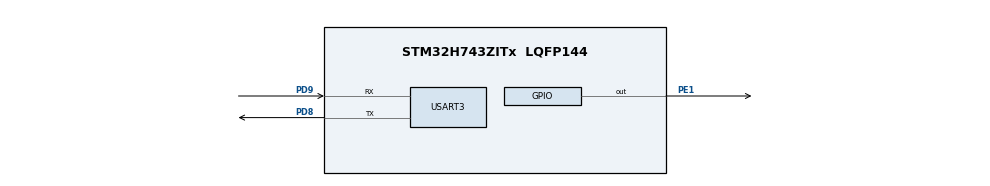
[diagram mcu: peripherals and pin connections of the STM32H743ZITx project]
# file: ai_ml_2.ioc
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CORTEX_M7.CPU_DCache=Enabled
CORTEX_M7.CPU_ICache=Enabled
CORTEX_M7.default_mode_Activation=1
Mcu.Family=STM32H7
Mcu.Name=STM32H743ZITx
Mcu.Package=LQFP144
NVIC.PriorityGroup=NVIC_PRIORITYGROUP_4
PC14-OSC32_IN\ (OSC32_IN).Mode=LSE-External-Oscillator
PC14-OSC32_IN\ (OSC32_IN).Signal=RCC_OSC32_IN
PC15-OSC32_OUT\ (OSC32_OUT).Mode=LSE-External-Oscillator
PC15-OSC32_OUT\ (OSC32_OUT).Signal=RCC_OSC32_OUT
PD8.Mode=Asynchronous
PD8.Signal=USART3_TX
PD9.Mode=Asynchronous
PD9.Signal=USART3_RX
PE1.Signal=GPIO_Output
PH0-OSC_IN\ (PH0).Mode=HSE-External-Oscillator
PH0-OSC_IN\ (PH0).Signal=RCC_OSC_IN
PH1-OSC_OUT\ (PH1).Mode=HSE-External-Oscillator
PH1-OSC_OUT\ (PH1).Signal=RCC_OSC_OUT
ProjectManager.HeapSize=0x800
ProjectManager.StackSize=0x800
ProjectManager.TargetToolchain=STM32CubeIDE
RCC.ADCFreq_Value=129000000
RCC.APB1Freq_Value=120000000
RCC.APB2Freq_Value=120000000
RCC.APB3Freq_Value=120000000
RCC.APB4Freq_Value=120000000
RCC.CortexFreq_Value=480000000
RCC.D1PPRE=RCC_APB3_DIV2
RCC.D2PPRE1=RCC_APB1_DIV2
RCC.D2PPRE2=RCC_APB2_DIV2
RCC.D3PPRE=RCC_APB4_DIV2
RCC.DIVM1=4
RCC.DIVN1=60
RCC.HCLKFreq_Value=240000000
RCC.HPRE=RCC_HCLK_DIV2
RCC.HSE_VALUE=8000000
RCC.PLL2FRACN=0
RCC.PLL3FRACN=0
RCC.PLLFRACN=0
RCC.SYSCLKFreq_VALUE=480000000
RCC.SYSCLKSource=RCC_SYSCLKSOURCE_PLLCLK
RCC.USBFreq_Value=480000000
STMicroelectronics.X-CUBE-AI.9.0.0.ActivationBufferSizeList=128
STMicroelectronics.X-CUBE-AI.9.0.0.ActivationBuffers=pool0
STMicroelectronics.X-CUBE-AI.9.0.0.ActivationNames=pool0
STMicroelectronics.X-CUBE-AI.9.0.0.ActivationSizes=AI_NETWORK_DATA_ACTIVATION_1_SIZE
STMicroelectronics.X-CUBE-AI.9.0.0.ApplicationCcDeviceJjApplication=ApplicationTemplate
STMicroelectronics.X-CUBE-AI.9.0.0.HeapSize=0x800
STMicroelectronics.X-CUBE-AI.9.0.0.InternalRamActivationBufferMaxSize=AI_NETWORK_DATA_ACTIVATIONS_SIZE
STMicroelectronics.X-CUBE-AI.9.0.0.LatestDirectoryUsed-3daab31856350568c4daed4f92a2e885c80895c0f46f9eb44de7cb06f3eb3ba4=C\:\\Users\\denni\\Downloads
STMicroelectronics.X-CUBE-AI.9.0.0.MaximumNumberOfInputLayer=1
STMicroelectronics.X-CUBE-AI.9.0.0.MaximumNumberOfOutputLayer=1
STMicroelectronics.X-CUBE-AI.9.0.0.MaximumSizeOfInputLayer=1
STMicroelectronics.X-CUBE-AI.9.0.0.MaximumSizeOfOutputLayer=1
STMicroelectronics.X-CUBE-AI.9.0.0.ModelActualCompression-3daab31856350568c4daed4f92a2e885c80895c0f46f9eb44de7cb06f3eb3ba4=0.0
STMicroelectronics.X-CUBE-AI.9.0.0.ModelCompression-3daab31856350568c4daed4f92a2e885c80895c0f46f9eb44de7cb06f3eb3ba4=None
STMicroelectronics.X-CUBE-AI.9.0.0.ModelFlashOccupation-3daab31856350568c4daed4f92a2e885c80895c0f46f9eb44de7cb06f3eb3ba4=1284
STMicroelectronics.X-CUBE-AI.9.0.0.ModelHashList=3daab31856350568c4daed4f92a2e885c80895c0f46f9eb44de7cb06f3eb3ba4
STMicroelectronics.X-CUBE-AI.9.0.0.ModelKind-3daab31856350568c4daed4f92a2e885c80895c0f46f9eb44de7cb06f3eb3ba4=TFLITE
STMicroelectronics.X-CUBE-AI.9.0.0.ModelMacc-3daab31856350568c4daed4f92a2e885c80895c0f46f9eb44de7cb06f3eb3ba4=353
STMicroelectronics.X-CUBE-AI.9.0.0.ModelName-3daab31856350568c4daed4f92a2e885c80895c0f46f9eb44de7cb06f3eb3ba4=network
STMicroelectronics.X-CUBE-AI.9.0.0.ModelNameList=network
STMicroelectronics.X-CUBE-AI.9.0.0.ModelRamOccupation-3daab31856350568c4daed4f92a2e885c80895c0f46f9eb44de7cb06f3eb3ba4=128
STMicroelectronics.X-CUBE-AI.9.0.0.ModelStructureFile-3daab31856350568c4daed4f92a2e885c80895c0f46f9eb44de7cb06f3eb3ba4=C\:\\Users\\denni\\Downloads\\sine_model.tflite
STMicroelectronics.X-CUBE-AI.9.0.0.ModelType-3daab31856350568c4daed4f92a2e885c80895c0f46f9eb44de7cb06f3eb3ba4=STM32Cube.AI MCU runtime
STMicroelectronics.X-CUBE-AI.9.0.0.ReadyForCodeGeneration=true
STMicroelectronics.X-CUBE-AI.9.0.0.StackSize=0x800
STMicroelectronics.X-CUBE-AI.9.0.0.WorkingBufferStartAddrList=0xFFFFFFFF
STMicroelectronics.X-CUBE-AI.9.0.0.XAaCUBEAaAICcArtificialOoIntelligenceJjCore=true
STMicroelectronics.X-CUBE-AI.9.0.0.copyWeightToRam=false
STMicroelectronics.X-CUBE-AI.9.0.0.copyWeightToRam-3daab31856350568c4daed4f92a2e885c80895c0f46f9eb44de7cb06f3eb3ba4=false
STMicroelectronics.X-CUBE-AI.9.0.0.customLayerConfigEnabled=false
STMicroelectronics.X-CUBE-AI.9.0.0.customLayerConfigEnabled-3daab31856350568c4daed4f92a2e885c80895c0f46f9eb44de7cb06f3eb3ba4=false
STMicroelectronics.X-CUBE-AI.9.0.0.noOnnxIoTranspose=false
STMicroelectronics.X-CUBE-AI.9.0.0.noOnnxIoTranspose-3daab31856350568c4daed4f92a2e885c80895c0f46f9eb44de7cb06f3eb3ba4=false
STMicroelectronics.X-CUBE-AI.9.0.0.useInputAllocation=true
STMicroelectronics.X-CUBE-AI.9.0.0.useInputAllocation-3daab31856350568c4daed4f92a2e885c80895c0f46f9eb44de7cb06f3eb3ba4=true
STMicroelectronics.X-CUBE-AI.9.0.0.useOutputAllocation=true
STMicroelectronics.X-CUBE-AI.9.0.0.useOutputAllocation-3daab31856350568c4daed4f92a2e885c80895c0f46f9eb44de7cb06f3eb3ba4=true
USART3.VirtualMode-Asynchronous=VM_ASYNC
VP_STMicroelectronics.X-CUBE-AI_VS_ArtificialOoIntelligenceJjXAaCUBEAaAI_9.0.0.Mode=ArtificialOoIntelligenceJjXAaCUBEAaAI
VP_STMicroelectronics.X-CUBE-AI_VS_DeviceJjApplication_9.0.0.Mode=DeviceJjApplication
board=custom

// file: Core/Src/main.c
/* USER CODE BEGIN Header */
/**
  ******************************************************************************
  * @file           : main.c
  * @brief          : Main program body
  ******************************************************************************
  * @attention
  *
  * Copyright (c) 2024 STMicroelectronics.
  * All rights reserved.
  *
  * This software is licensed under terms that can be found in the LICENSE file
  * in the root directory of this software component.
  * If no LICENSE file comes with this software, it is provided AS-IS.
  *
  ******************************************************************************
  */
/* USER CODE END Header */
#include "main.h"
#include "usart.h"
#include "gpio.h"
#include "app_x-cube-ai.h"

void SystemClock_Config(void);
static void MPU_Config(void);

int main(void)
{

  /* USER CODE BEGIN 1 */
	//uint32_t in_number = 0;
	//uint32_t out_number = 0;
  /* USER CODE END 1 */

  /* MPU Configuration--------------------------------------------------------*/
  MPU_Config();

  /* Enable the CPU Cache */

  /* Enable I-Cache---------------------------------------------------------*/
  SCB_EnableICache();

  /* Enable D-Cache---------------------------------------------------------*/
  SCB_EnableDCache();

  /* MCU Configuration--------------------------------------------------------*/

  /* Reset of all peripherals, Initializes the Flash interface and the Systick. */
  HAL_Init();

  /* Configure the system clock */
  SystemClock_Config();

  /* Initialize all configured peripherals */
  MX_GPIO_Init();
  MX_USART3_UART_Init();
  MX_X_CUBE_AI_Init();

  /* Infinite loop */
  while (1)
  {
	  HAL_GPIO_WritePin(GPIOE,GPIO_PIN_1,GPIO_PIN_SET);
  MX_X_CUBE_AI_Process();
  }
}

void SystemClock_Config(void)
{
  RCC_OscInitTypeDef RCC_OscInitStruct = {0};
  RCC_ClkInitTypeDef RCC_ClkInitStruct = {0};

  /** Supply configuration update enable
  */
  HAL_PWREx_ConfigSupply(PWR_LDO_SUPPLY);

  /** Configure the main internal regulator output voltage
  */
  __HAL_PWR_VOLTAGESCALING_CONFIG(PWR_REGULATOR_VOLTAGE_SCALE1);

  while(!__HAL_PWR_GET_FLAG(PWR_FLAG_VOSRDY)) {}

  __HAL_RCC_SYSCFG_CLK_ENABLE();
  __HAL_PWR_VOLTAGESCALING_CONFIG(PWR_REGULATOR_VOLTAGE_SCALE0);

  while(!__HAL_PWR_GET_FLAG(PWR_FLAG_VOSRDY)) {}

  /** Initializes the RCC Oscillators according to the specified parameters
  * in the RCC_OscInitTypeDef structure.
  */
  RCC_OscInitStruct.OscillatorType = RCC_OSCILLATORTYPE_HSI;
  RCC_OscInitStruct.HSIState = RCC_HSI_DIV1;
  RCC_OscInitStruct.HSICalibrationValue = RCC_HSICALIBRATION_DEFAULT;
  RCC_OscInitStruct.PLL.PLLState = RCC_PLL_ON;
  RCC_OscInitStruct.PLL.PLLSource = RCC_PLLSOURCE_HSI;
  RCC_OscInitStruct.PLL.PLLM = 4;
  RCC_OscInitStruct.PLL.PLLN = 60;
  RCC_OscInitStruct.PLL.PLLP = 2;
  RCC_OscInitStruct.PLL.PLLQ = 2;
  RCC_OscInitStruct.PLL.PLLR = 2;
  RCC_OscInitStruct.PLL.PLLRGE = RCC_PLL1VCIRANGE_3;
  RCC_OscInitStruct.PLL.PLLVCOSEL = RCC_PLL1VCOWIDE;
  RCC_OscInitStruct.PLL.PLLFRACN = 0;
  if (HAL_RCC_OscConfig(&RCC_OscInitStruct) != HAL_OK)
  {
    Error_Handler();
  }

  /** Initializes the CPU, AHB and APB buses clocks
  */
  RCC_ClkInitStruct.ClockType = RCC_CLOCKTYPE_HCLK|RCC_CLOCKTYPE_SYSCLK
                              |RCC_CLOCKTYPE_PCLK1|RCC_CLOCKTYPE_PCLK2
                              |RCC_CLOCKTYPE_D3PCLK1|RCC_CLOCKTYPE_D1PCLK1;
  RCC_ClkInitStruct.SYSCLKSource = RCC_SYSCLKSOURCE_PLLCLK;
  RCC_ClkInitStruct.SYSCLKDivider = RCC_SYSCLK_DIV1;
  RCC_ClkInitStruct.AHBCLKDivider = RCC_HCLK_DIV2;
  RCC_ClkInitStruct.APB3CLKDivider = RCC_APB3_DIV2;
  RCC_ClkInitStruct.APB1CLKDivider = RCC_APB1_DIV2;
  RCC_ClkInitStruct.APB2CLKDivider = RCC_APB2_DIV2;
  RCC_ClkInitStruct.APB4CLKDivider = RCC_APB4_DIV2;

  if (HAL_RCC_ClockConfig(&RCC_ClkInitStruct, FLASH_LATENCY_4) != HAL_OK)
  {
    Error_Handler();
  }
}

 /* MPU Configuration */

void MPU_Config(void)
{
  MPU_Region_InitTypeDef MPU_InitStruct = {0};

  /* Disables the MPU */
  HAL_MPU_Disable();

  /** Initializes and configures the Region and the memory to be protected
  */
  MPU_InitStruct.Enable = MPU_REGION_ENABLE;
  MPU_InitStruct.Number = MPU_REGION_NUMBER0;
  MPU_InitStruct.BaseAddress = 0x0;
  MPU_InitStruct.Size = MPU_REGION_SIZE_4GB;
  MPU_InitStruct.SubRegionDisable = 0x87;
  MPU_InitStruct.TypeExtField = MPU_TEX_LEVEL0;
  MPU_InitStruct.AccessPermission = MPU_REGION_NO_ACCESS;
  MPU_InitStruct.DisableExec = MPU_INSTRUCTION_ACCESS_DISABLE;
  MPU_InitStruct.IsShareable = MPU_ACCESS_SHAREABLE;
  MPU_InitStruct.IsCacheable = MPU_ACCESS_NOT_CACHEABLE;
  MPU_InitStruct.IsBufferable = MPU_ACCESS_NOT_BUFFERABLE;

  HAL_MPU_ConfigRegion(&MPU_InitStruct);
  /* Enables the MPU */
  HAL_MPU_Enable(MPU_PRIVILEGED_DEFAULT);

}

void Error_Handler(void)
{
  __disable_irq();
  while (1)
  {
  }
}
